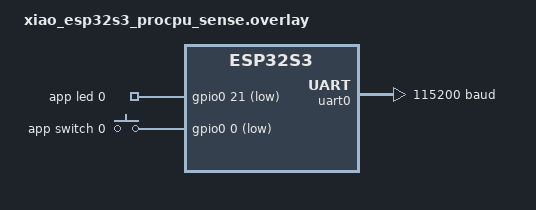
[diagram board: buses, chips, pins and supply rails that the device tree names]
/ {
    gpiocustom {
        compatible = "gpio-keys";
        appled0: appled_0 {
            gpios = <&gpio0 21 GPIO_ACTIVE_LOW>;
            label = "app led 0";
        };

        appsw_0: appsw_0 {
            gpios = <&gpio0 0 (GPIO_PULL_UP | GPIO_ACTIVE_LOW)>;
            label = "app switch 0";
        };
    };

    aliases {
        appled0 = &appled0;
        appsw0 = &appsw_0;
        appuart0 = &uart0;
    };
};

&uart0 {
	status = "okay";
	current-speed = <115200>;
	pinctrl-0 = <&uart0_default>;
	pinctrl-names = "default";
};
